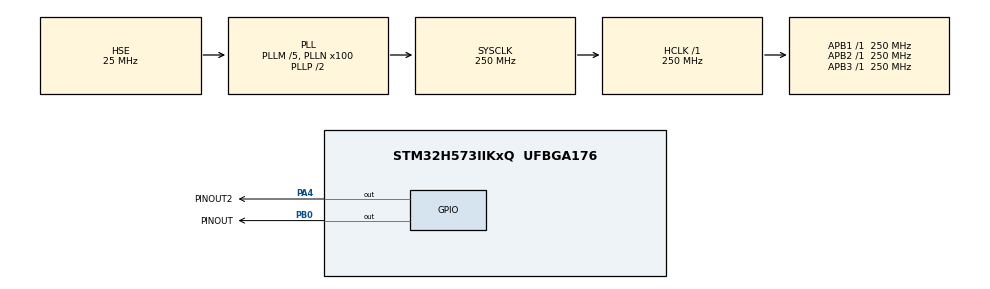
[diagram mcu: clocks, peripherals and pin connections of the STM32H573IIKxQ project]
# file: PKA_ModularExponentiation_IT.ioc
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CORTEX_M33_NS.userName=CORTEX_M33
Mcu.Family=STM32H5
Mcu.Name=STM32H573IIKxQ
Mcu.Package=UFBGA176
NVIC.PKA_IRQn=true\:0\:0\:false\:false\:true\:true\:true\:true
NVIC.PriorityGroup=NVIC_PRIORITYGROUP_4
PA4.GPIO_Label=PINOUT2
PA4.GPIO_Speed=GPIO_SPEED_FREQ_VERY_HIGH
PA4.PinState=GPIO_PIN_SET
PA4.Signal=GPIO_Output
PB0.GPIO_Label=PINOUT
PB0.GPIO_Speed=GPIO_SPEED_FREQ_VERY_HIGH
PB0.PinState=GPIO_PIN_SET
PB0.Signal=GPIO_Output
PH0-OSC_IN(PH0).Mode=HSE-DIG-External-Clock-Source
PH0-OSC_IN(PH0).Signal=RCC_OSC_IN
ProjectManager.HeapSize=0x200
ProjectManager.StackSize=0x400
ProjectManager.TargetToolchain=STM32CubeIDE
RCC.ADCFreq_Value=250000000
RCC.AHBFreq_Value=250000000
RCC.APB1Freq_Value=250000000
RCC.APB1TimFreq_Value=250000000
RCC.APB2Freq_Value=250000000
RCC.APB2TimFreq_Value=250000000
RCC.APB3Freq_Value=250000000
RCC.CSI_VALUE=4000000
RCC.CortexFreq_Value=250000000
RCC.EPOD_VALUE=25000000
RCC.HCLKFreq_Value=250000000
RCC.HSE_VALUE=25000000
RCC.HSI48_VALUE=48000000
RCC.HSIDiv=RCC_HSI_DIV1
RCC.HSI_VALUE=64000000
RCC.LSE_VALUE=32768
RCC.LSIRC_VALUE=32000
RCC.PLLM=5
RCC.PLLN=100
RCC.PLLSourceVirtual=RCC_PLL1_SOURCE_HSE
RCC.SYSCLKFreq_VALUE=250000000
RCC.SYSCLKSource=RCC_SYSCLKSOURCE_PLLCLK
RCC.USBFreq_Value=48000000
RCC.VCOOutputFreq_Value=500000000
VP_ICACHE_VS_ICACHE.Mode=DefaultMode
VP_PKA_VS_PKA.Mode=PKA_Activate
VP_PWR_VS_SECSignals.Mode=Security/Privilege
VP_RNG_VS_RNG.Mode=RNG_Activate
board=STM32H573I-DK

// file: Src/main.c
/* USER CODE BEGIN Header */
/**
  ******************************************************************************
  * @file    PKA/PKA_ModularExponentiation_IT/Src/main.c
  * @author  MCD Application Team
  * @brief   This example describes how to configure and use PKA through
  *          the STM32H5xx HAL API.
  ******************************************************************************
  * @attention
  *
  * Copyright (c) 2023 STMicroelectronics.
  * All rights reserved.
  *
  * This software is licensed under terms that can be found in the LICENSE file
  * in the root directory of this software component.
  * If no LICENSE file comes with this software, it is provided AS-IS.
  *
  ******************************************************************************
  */
/* USER CODE END Header */
#include "main.h"

/* USER CODE BEGIN PD */
#define LOW GPIO_PIN_RESET
#define HIGH GPIO_PIN_SET
/* USER CODE END PD */

PKA_HandleTypeDef hpka;

RNG_HandleTypeDef hrng;

/* USER CODE BEGIN PV */
PKA_ModExpInTypeDef in = {0};
uint8_t decipheredBuffer[256];
uint8_t cipheredBuffer[256];
__IO uint32_t operationComplete = 0;
/* USER CODE END PV */

void SystemClock_Config(void);
static void MX_GPIO_Init(void);
static void MX_ICACHE_Init(void);
static void MX_RNG_Init(void);
static void MX_PKA_Init(void);

int main(void)
{
  /* USER CODE BEGIN 1 */
  /* STM32H5xx HAL library initialization:
       - Systick timer is configured by default as source of time base, but user
             can eventually implement his proper time base source (a general purpose
             timer for example or other time source), keeping in mind that Time base
             duration should be kept 1ms since PPP_TIMEOUT_VALUEs are defined and
             handled in milliseconds basis.
       - Set NVIC Group Priority to 4
       - Low Level Initialization
     */
  /* USER CODE END 1 */

  /* MCU Configuration--------------------------------------------------------*/

  /* Reset of all peripherals, Initializes the Flash interface and the Systick. */
  HAL_Init();

  /* Configure the system clock */
  SystemClock_Config();

  /* USER CODE BEGIN SysInit */
  /* Configure LED1 */
  BSP_LED_Init(LED1);

  /* USER CODE END SysInit */

  /* Initialize all configured peripherals */
  MX_GPIO_Init();
  MX_ICACHE_Init();
  MX_RNG_Init();
  MX_PKA_Init();
  /* USER CODE BEGIN 2 */
  /* Set input parameters */
  in.expSize = rsa_pub_2048_publicExponent_len;
  in.OpSize  = rsa_pub_2048_modulus_len;
  in.pOp1    = plaintext_bin;
  in.pExp    = rsa_pub_2048_publicExponent;
  in.pMod    = rsa_pub_2048_modulus;

//  HAL_GPIO_WritePin(PINOUT_GPIO_Port, PINOUT_Pin, HIGH);
//  HAL_GPIO_WritePin(PINOUT2_GPIO_Port, PINOUT2_Pin, HIGH);
//
//  HAL_Delay(50);
//
//  HAL_GPIO_WritePin(PINOUT_GPIO_Port, PINOUT_Pin, LOW);
//  HAL_GPIO_WritePin(PINOUT2_GPIO_Port, PINOUT2_Pin, LOW);
//
//
  HAL_GPIO_WritePin(PINOUT_GPIO_Port, PINOUT_Pin, HIGH);

  /* Start the modular exponentiation (ciphering step) */
  if(HAL_PKA_ModExp_IT(&hpka, &in) != HAL_OK)
  {
    Error_Handler();
  }

  /* Wait until the interrupt is triggered */
  while(operationComplete == 0);
  operationComplete = 0;

  /* Copy the results to user specified space */
  HAL_PKA_ModExp_GetResult(&hpka , cipheredBuffer);

  /* (Facultative) Compare the computed and expected result */
  if (memcmp(cipheredBuffer, ciphertext_bin, ciphertext_bin_len) != 0)
  {
    Error_Handler();
  }

  /* Set input parameters */
  in.expSize = rsa_priv_2048_privateExponent_len;
  in.OpSize  = rsa_pub_2048_modulus_len;
  in.pOp1    = ciphertext_bin;
  in.pExp    = rsa_priv_2048_privateExponent;
  in.pMod    = rsa_priv_2048_modulus;

  /* Start the modular exponentiation (deciphering step) */
  if(HAL_PKA_ModExp_IT(&hpka, &in) != HAL_OK)
  {
    Error_Handler();
  }

  /* Wait until the interrupt is triggered */
  while(operationComplete == 0);

  /* Copy the results to user specified space */
  HAL_PKA_ModExp_GetResult(&hpka , decipheredBuffer);

  /* (Facultative) Compare the computed and expected result */
  if (memcmp(decipheredBuffer, plaintext_bin, plaintext_bin_len) != 0)
  {
    Error_Handler();
  }

  /* Deinitialize the PKA */
  if(HAL_PKA_DeInit(&hpka) != HAL_OK)
  {
    Error_Handler();
  }

  /* Success */
  HAL_GPIO_WritePin(PINOUT_GPIO_Port, PINOUT_Pin, LOW);
  operationComplete = 3;
  BSP_LED_On(LED1);

  /* USER CODE END 2 */

  /* Infinite loop */
  /* USER CODE BEGIN WHILE */
  while (1)
  {
//	  HAL_GPIO_WritePin(PINOUT_GPIO_Port, PINOUT_Pin, HIGH);

    /* USER CODE END WHILE */
//	  HAL_GPIO_WritePin(PINOUT2_GPIO_Port, PINOUT2_Pin, HIGH);
//	  HAL_GPIO_WritePin(PINOUT_GPIO_Port, PINOUT_Pin, HIGH);
  }
}

void SystemClock_Config(void)
{
  RCC_OscInitTypeDef RCC_OscInitStruct = {0};
  RCC_ClkInitTypeDef RCC_ClkInitStruct = {0};

  /** Configure the main internal regulator output voltage
  */
  __HAL_PWR_VOLTAGESCALING_CONFIG(PWR_REGULATOR_VOLTAGE_SCALE0);

  while(!__HAL_PWR_GET_FLAG(PWR_FLAG_VOSRDY)) {}

  /** Initializes the RCC Oscillators according to the specified parameters
  * in the RCC_OscInitTypeDef structure.
  */
  RCC_OscInitStruct.OscillatorType = RCC_OSCILLATORTYPE_HSI48|RCC_OSCILLATORTYPE_HSE;
  RCC_OscInitStruct.HSEState = RCC_HSE_BYPASS_DIGITAL;
  RCC_OscInitStruct.HSI48State = RCC_HSI48_ON;
  RCC_OscInitStruct.PLL.PLLState = RCC_PLL_ON;
  RCC_OscInitStruct.PLL.PLLSource = RCC_PLL1_SOURCE_HSE;
  RCC_OscInitStruct.PLL.PLLM = 5;
  RCC_OscInitStruct.PLL.PLLN = 100;
  RCC_OscInitStruct.PLL.PLLP = 2;
  RCC_OscInitStruct.PLL.PLLQ = 2;
  RCC_OscInitStruct.PLL.PLLR = 2;
  RCC_OscInitStruct.PLL.PLLRGE = RCC_PLL1_VCIRANGE_2;
  RCC_OscInitStruct.PLL.PLLVCOSEL = RCC_PLL1_VCORANGE_WIDE;
  RCC_OscInitStruct.PLL.PLLFRACN = 0;
  if (HAL_RCC_OscConfig(&RCC_OscInitStruct) != HAL_OK)
  {
    Error_Handler();
  }

  /** Initializes the CPU, AHB and APB buses clocks
  */
  RCC_ClkInitStruct.ClockType = RCC_CLOCKTYPE_HCLK|RCC_CLOCKTYPE_SYSCLK
                              |RCC_CLOCKTYPE_PCLK1|RCC_CLOCKTYPE_PCLK2
                              |RCC_CLOCKTYPE_PCLK3;
  RCC_ClkInitStruct.SYSCLKSource = RCC_SYSCLKSOURCE_PLLCLK;
  RCC_ClkInitStruct.AHBCLKDivider = RCC_SYSCLK_DIV1;
  RCC_ClkInitStruct.APB1CLKDivider = RCC_HCLK_DIV1;
  RCC_ClkInitStruct.APB2CLKDivider = RCC_HCLK_DIV1;
  RCC_ClkInitStruct.APB3CLKDivider = RCC_HCLK_DIV1;

  if (HAL_RCC_ClockConfig(&RCC_ClkInitStruct, FLASH_LATENCY_5) != HAL_OK)
  {
    Error_Handler();
  }
}

static void MX_ICACHE_Init(void)
{

  /** Enable instruction cache (default 2-ways set associative cache)
  */
  if (HAL_ICACHE_Enable() != HAL_OK)
  {
    Error_Handler();
  }

}

static void MX_PKA_Init(void)
{

  hpka.Instance = PKA;
  if (HAL_PKA_Init(&hpka) != HAL_OK)
  {
    Error_Handler();
  }

}

static void MX_RNG_Init(void)
{

  hrng.Instance = RNG;
  hrng.Init.ClockErrorDetection = RNG_CED_ENABLE;
  if (HAL_RNG_Init(&hrng) != HAL_OK)
  {
    Error_Handler();
  }

}

static void MX_GPIO_Init(void)
{
  GPIO_InitTypeDef GPIO_InitStruct = {0};

  /* GPIO Ports Clock Enable */
  __HAL_RCC_GPIOH_CLK_ENABLE();
  __HAL_RCC_GPIOA_CLK_ENABLE();
  __HAL_RCC_GPIOB_CLK_ENABLE();

  /*Configure GPIO pin Output Level */
  HAL_GPIO_WritePin(PINOUT2_GPIO_Port, PINOUT2_Pin, LOW);

  /*Configure GPIO pin Output Level */
  HAL_GPIO_WritePin(PINOUT_GPIO_Port, PINOUT_Pin, LOW);

  /*Configure GPIO pin : PINOUT2_Pin */
  GPIO_InitStruct.Pin = PINOUT2_Pin;
  GPIO_InitStruct.Mode = GPIO_MODE_OUTPUT_PP;
  GPIO_InitStruct.Pull = GPIO_NOPULL;
  GPIO_InitStruct.Speed = GPIO_SPEED_FREQ_VERY_HIGH;
  HAL_GPIO_Init(PINOUT2_GPIO_Port, &GPIO_InitStruct);

  /*Configure GPIO pin : PINOUT_Pin */
  GPIO_InitStruct.Pin = PINOUT_Pin;
  GPIO_InitStruct.Mode = GPIO_MODE_OUTPUT_PP;
  GPIO_InitStruct.Pull = GPIO_NOPULL;
  GPIO_InitStruct.Speed = GPIO_SPEED_FREQ_VERY_HIGH;
  HAL_GPIO_Init(PINOUT_GPIO_Port, &GPIO_InitStruct);

}

/* USER CODE BEGIN 4 */
/**
  * @brief  Process completed callback.
  * @param  hpka PKA handle
  * @retval None
  */
void HAL_PKA_OperationCpltCallback(PKA_HandleTypeDef *hpka)
{
  operationComplete = 1;
}

/**
  * @brief  Error callback.
  * @param  hpka PKA handle
  * @retval None
  */
void HAL_PKA_ErrorCallback(PKA_HandleTypeDef *hpka)
{
  Error_Handler();
}
/* USER CODE END 4 */

void Error_Handler(void)
{
  /* USER CODE BEGIN Error_Handler_Debug */
  /* User can add his own implementation to report the HAL error return state */
  operationComplete = 2;
  while (1)
  {
    /* Error if LED1 is slowly blinking (1 sec. period) */
    BSP_LED_Toggle(LED1);
    HAL_Delay(1000);
  }
  /* USER CODE END Error_Handler_Debug */
}
